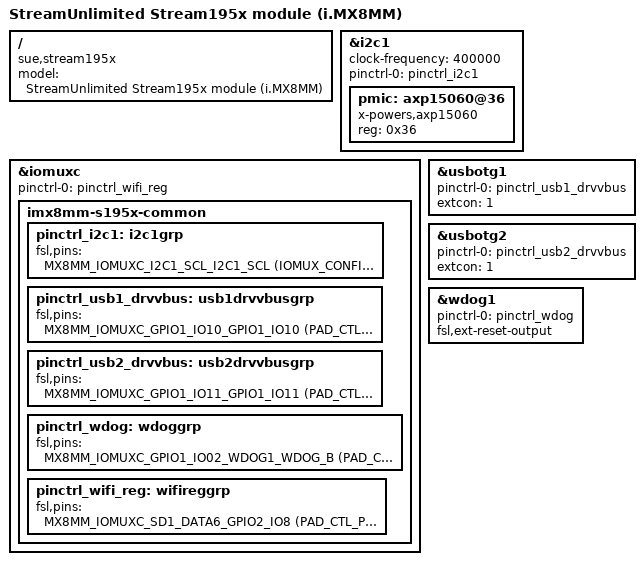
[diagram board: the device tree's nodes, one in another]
#include "fsl-imx8mm.dtsi"
#include "fsl-imx8mm-pad.dtsi"

/ {
	model = "StreamUnlimited Stream195x module (i.MX8MM)";
	compatible = "sue,stream195x", "fsl,imx8mm";
};

&i2c1 {
	clock-frequency = <400000>;
	pinctrl-names = "default";
	pinctrl-0 = <&pinctrl_i2c1>;
	status = "okay";

	pmic: axp15060@36 {
		compatible = "x-powers,axp15060";
		reg = <0x36>;
	};
};

&iomuxc {
	pinctrl-names = "default";
	pinctrl-0 = <&pinctrl_wifi_reg>;

	imx8mm-s195x-common {
		pinctrl_i2c1: i2c1grp {
			fsl,pins = <
				MX8MM_IOMUXC_I2C1_SCL_I2C1_SCL	(IOMUX_CONFIG_SION | PAD_CTL_PE_UP | PAD_CTL_HYS | PAD_CTL_FAST | PAD_CTL_DSE6x)
				MX8MM_IOMUXC_I2C1_SDA_I2C1_SDA	(IOMUX_CONFIG_SION | PAD_CTL_PE_UP | PAD_CTL_HYS | PAD_CTL_FAST | PAD_CTL_DSE6x)
			>;
		};

		pinctrl_usb1_drvvbus: usb1drvvbusgrp {
			fsl,pins = <
				MX8MM_IOMUXC_GPIO1_IO10_GPIO1_IO10	(PAD_CTL_PE_DOWN | PAD_CTL_HYS)
			>;
		};

		pinctrl_usb2_drvvbus: usb2drvvbusgrp {
			fsl,pins = <
				MX8MM_IOMUXC_GPIO1_IO11_GPIO1_IO11	(PAD_CTL_PE_DOWN | PAD_CTL_HYS)
			>;
		};

		pinctrl_wdog: wdoggrp {
			fsl,pins = <
				MX8MM_IOMUXC_GPIO1_IO02_WDOG1_WDOG_B	(PAD_CTL_PE_UP | PAD_CTL_HYS | PAD_CTL_DSE6x)
			>;
		};

		pinctrl_wifi_reg: wifireggrp {
			fsl,pins = <
				MX8MM_IOMUXC_SD1_DATA6_GPIO2_IO8	(PAD_CTL_PE_UP | PAD_CTL_HYS)
				MX8MM_IOMUXC_SD1_RESET_B_GPIO2_IO10	(PAD_CTL_PE_UP | PAD_CTL_HYS)
			>;
		};
	};
};

&usbotg1 {
	pinctrl-names = "default";
	pinctrl-0 = <&pinctrl_usb1_drvvbus>;
	status = "okay";

	/*
	 * Setting extcon makes sure that the USB driver will
	 * call `board_ehci_usb_phy_mode()` to determine if the
	 * port is a device or host.
	 */
	extcon = <1>;
};

&usbotg2 {
	pinctrl-names = "default";
	pinctrl-0 = <&pinctrl_usb2_drvvbus>;
	status = "okay";
	extcon = <1>;
};

&wdog1 {
	pinctrl-names = "default";
	pinctrl-0 = <&pinctrl_wdog>;
	fsl,ext-reset-output;
	status = "okay";
};
